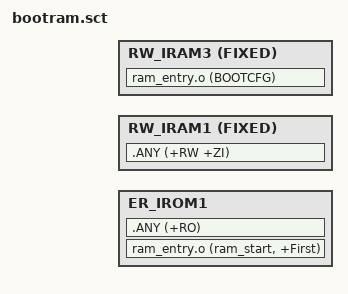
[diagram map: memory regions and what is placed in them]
#! armcc -E

#include "..\..\..\inc\bootram_mem.h"

; *************************************************************
; *** Scatter-Loading Description File generated by uVision ***
; *************************************************************

LR_IROM1 0x00200000 BOOTRAM_SIZE  {    ; load region size_region

	ER_IROM1 BOOTRAM_CODE_START BOOTRAM_CODE_SIZE  {  ; load address = execution address
	   ram_entry.o (ram_start, +First)
		.ANY (+RO)
	}

	RW_IRAM1 BOOTRAM_RW_START FIXED BOOTRAM_RW_SIZE {  ; RW data
		.ANY (+RW +ZI)
	}


	RW_IRAM3 BOOTRAM_BOOTCFG_START FIXED BOOTRAM_BOOTCFG_SIZE {  ; RW data
		ram_entry.o (BOOTCFG)
	}

}

